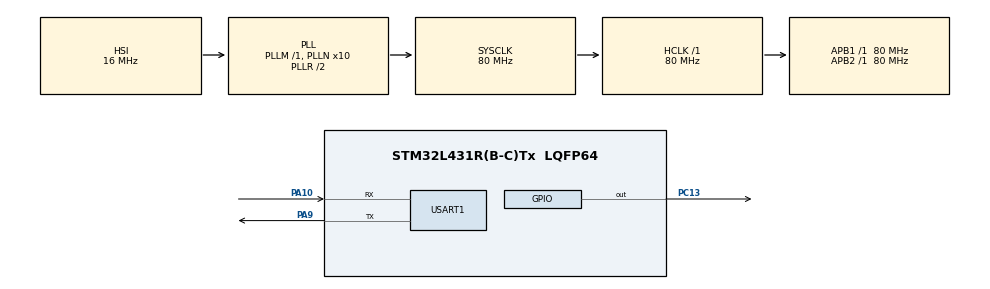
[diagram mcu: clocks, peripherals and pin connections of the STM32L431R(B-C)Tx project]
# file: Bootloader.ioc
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Mcu.Family=STM32L4
Mcu.Name=STM32L431R(B-C)Tx
Mcu.Package=LQFP64
NVIC.PriorityGroup=NVIC_PRIORITYGROUP_4
NVIC.USART1_IRQn=true\:1\:0\:true\:false\:true\:true\:true\:true
PA10.Mode=Asynchronous
PA10.Signal=USART1_RX
PA13\ (JTMS-SWDIO).Mode=Serial_Wire
PA13\ (JTMS-SWDIO).Signal=SYS_JTMS-SWDIO
PA14\ (JTCK-SWCLK).Mode=Serial_Wire
PA14\ (JTCK-SWCLK).Signal=SYS_JTCK-SWCLK
PA9.Mode=Asynchronous
PA9.Signal=USART1_TX
PC13.Signal=GPIO_Output
ProjectManager.HeapSize=0x200
ProjectManager.StackSize=0x400
ProjectManager.TargetToolchain=STM32CubeIDE
RCC.ADCFreq_Value=64000000
RCC.AHBFreq_Value=80000000
RCC.APB1Freq_Value=80000000
RCC.APB1TimFreq_Value=80000000
RCC.APB2Freq_Value=80000000
RCC.APB2TimFreq_Value=80000000
RCC.CortexFreq_Value=80000000
RCC.HCLKFreq_Value=80000000
RCC.HSE_VALUE=16000000
RCC.HSI48_VALUE=48000000
RCC.HSI_VALUE=16000000
RCC.LSE_VALUE=32768
RCC.MSI_VALUE=4000000
RCC.PLLN=10
RCC.PLLSourceVirtual=RCC_PLLSOURCE_HSI
RCC.SYSCLKFreq_VALUE=80000000
RCC.SYSCLKSource=RCC_SYSCLKSOURCE_PLLCLK
RCC.VCOOutputFreq_Value=160000000
USART1.VirtualMode-Asynchronous=VM_ASYNC
VP_IWDG_VS_IWDG.Mode=IWDG_Activate
board=custom

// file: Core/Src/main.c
/* USER CODE BEGIN Header */
/**
 ******************************************************************************
 * @file           : main.c
 * @brief          : Main program body
 ******************************************************************************
 * @attention
 *
 * Copyright (c) 2024 STMicroelectronics.
 * All rights reserved.
 *
 * This software is licensed under terms that can be found in the LICENSE file
 * in the root directory of this software component.
 * If no LICENSE file comes with this software, it is provided AS-IS.
 *
 ******************************************************************************
 */
/* USER CODE END Header */
#include "main.h"

/* USER CODE BEGIN Includes */
#include <string.h>
#include <stdlib.h>
#include "foo.h"
#include "wdt.h"
#include "flash.h"
#include "task_list.h"
#include "bootloader.h"
/* USER CODE END Includes */

/* USER CODE BEGIN PD */
#define HW_VERSION 	0x7d2
#define FW_VERSION 	0x12
#define PROT_VER	0x1000
#define WAIT_TOFF	(0x3E8 * 600)
/* USER CODE END PD */

IWDG_HandleTypeDef hiwdg;

UART_HandleTypeDef huart1;

/* USER CODE BEGIN PV */
static struct foo_device dev;
static struct task_queue  serial_queue;
/* USER CODE END PV */

void SystemClock_Config(void);
static void MX_GPIO_Init(void);
static void MX_USART1_UART_Init(void);
static void MX_IWDG_Init(void);
/* USER CODE BEGIN PFP */
static boot_options_t get_flag(void);
/* USER CODE END PFP */

/* USER CODE BEGIN 0 */

void uart_receive(struct serdev_device *dev, u8 *buf, u32 len) {
	struct task_struct *task = (struct task_struct *)buf;
	put_task_to_queue(&serial_queue, *task);
	serial_start_receiving(dev);
}

/* USER CODE END 0 */

int main(void)
{
  /* USER CODE BEGIN 1 */
	init_queue(&serial_queue, 5);
	dev.serial.bus = &huart1;
	dev.serial.receive_buf = uart_receive;
	dev.button_trigger = 1;
	dev.firmware_version = FW_VERSION;
	dev.hardware_version = HW_VERSION;
	dev.protocol_version = PROT_VER;
	dev.watting_time_off = WAIT_TOFF;
	get_serial_number(&dev);

#ifdef FLASH_LARGE
  dev.firmware_address = FIRMWARE_TEM;
#else
	dev.firmware_address = FIRMWARE_ADDRESS;
#endif
  /* USER CODE END 1 */

  /* MCU Configuration--------------------------------------------------------*/

  /* Reset of all peripherals, Initializes the Flash interface and the Systick. */
  HAL_Init();

  /* Configure the system clock */
  SystemClock_Config();

  /* Initialize all configured peripherals */
  MX_GPIO_Init();
  MX_USART1_UART_Init();
  MX_IWDG_Init();
  /* USER CODE BEGIN 2 */
  serdev_device_register(&dev.serial);
	watchdog_set_timeout(&hiwdg, TIMEOUT_32_SEC);
	HAL_GPIO_WritePin(GPIOC, GPIO_PIN_13, GPIO_PIN_RESET);

	boot_options_t flag_r = get_flag();
	switch (flag_r) {
		case UPDATE_MODE:
			u32 size = 0;
			flash_read(VAR_BASE_ADDRESS + FW_LENGTH_OFFSET, &size, sizeof(u32));
			update_firmware(size);
			boot_options_t flag = BOOTING_MODE;
			flash_write_data(VAR_BASE_ADDRESS + FLAG_OFFSET, (u8 *)&flag, sizeof(boot_options_t));
			HAL_NVIC_SystemReset();
			break;

		case BOOTLOADER_MODE:
			serial_start_receiving(&dev.serial);
			break;

		default:
			goto_application();
	}

  /* USER CODE END 2 */

  /* Infinite loop */
	while (1) {

    /* USER CODE BEGIN 3 */
		if (!queue_is_empty(&serial_queue)) {
			handle_request(&dev, get_new_task(&serial_queue).buf);
		}
		ping_to_watchdog(&hiwdg);
	}
  /* USER CODE END 3 */
}

void SystemClock_Config(void)
{
  RCC_OscInitTypeDef RCC_OscInitStruct = {0};
  RCC_ClkInitTypeDef RCC_ClkInitStruct = {0};

  /** Configure the main internal regulator output voltage
  */
  if (HAL_PWREx_ControlVoltageScaling(PWR_REGULATOR_VOLTAGE_SCALE1) != HAL_OK)
  {
    Error_Handler();
  }

  /** Initializes the RCC Oscillators according to the specified parameters
  * in the RCC_OscInitTypeDef structure.
  */
  RCC_OscInitStruct.OscillatorType = RCC_OSCILLATORTYPE_HSI|RCC_OSCILLATORTYPE_LSI;
  RCC_OscInitStruct.HSIState = RCC_HSI_ON;
  RCC_OscInitStruct.HSICalibrationValue = RCC_HSICALIBRATION_DEFAULT;
  RCC_OscInitStruct.LSIState = RCC_LSI_ON;
  RCC_OscInitStruct.PLL.PLLState = RCC_PLL_ON;
  RCC_OscInitStruct.PLL.PLLSource = RCC_PLLSOURCE_HSI;
  RCC_OscInitStruct.PLL.PLLM = 1;
  RCC_OscInitStruct.PLL.PLLN = 10;
  RCC_OscInitStruct.PLL.PLLP = RCC_PLLP_DIV7;
  RCC_OscInitStruct.PLL.PLLQ = RCC_PLLQ_DIV2;
  RCC_OscInitStruct.PLL.PLLR = RCC_PLLR_DIV2;
  if (HAL_RCC_OscConfig(&RCC_OscInitStruct) != HAL_OK)
  {
    Error_Handler();
  }

  /** Initializes the CPU, AHB and APB buses clocks
  */
  RCC_ClkInitStruct.ClockType = RCC_CLOCKTYPE_HCLK|RCC_CLOCKTYPE_SYSCLK
                              |RCC_CLOCKTYPE_PCLK1|RCC_CLOCKTYPE_PCLK2;
  RCC_ClkInitStruct.SYSCLKSource = RCC_SYSCLKSOURCE_PLLCLK;
  RCC_ClkInitStruct.AHBCLKDivider = RCC_SYSCLK_DIV1;
  RCC_ClkInitStruct.APB1CLKDivider = RCC_HCLK_DIV1;
  RCC_ClkInitStruct.APB2CLKDivider = RCC_HCLK_DIV1;

  if (HAL_RCC_ClockConfig(&RCC_ClkInitStruct, FLASH_LATENCY_4) != HAL_OK)
  {
    Error_Handler();
  }
}

static void MX_IWDG_Init(void)
{

  hiwdg.Instance = IWDG;
  hiwdg.Init.Prescaler = IWDG_PRESCALER_4;
  hiwdg.Init.Window = 4095;
  hiwdg.Init.Reload = 4095;
  if (HAL_IWDG_Init(&hiwdg) != HAL_OK)
  {
    Error_Handler();
  }

}

static void MX_USART1_UART_Init(void)
{

  huart1.Instance = USART1;
  huart1.Init.BaudRate = 115200;
  huart1.Init.WordLength = UART_WORDLENGTH_8B;
  huart1.Init.StopBits = UART_STOPBITS_1;
  huart1.Init.Parity = UART_PARITY_NONE;
  huart1.Init.Mode = UART_MODE_TX_RX;
  huart1.Init.HwFlowCtl = UART_HWCONTROL_NONE;
  huart1.Init.OverSampling = UART_OVERSAMPLING_16;
  huart1.Init.OneBitSampling = UART_ONE_BIT_SAMPLE_DISABLE;
  huart1.AdvancedInit.AdvFeatureInit = UART_ADVFEATURE_NO_INIT;
  if (HAL_UART_Init(&huart1) != HAL_OK)
  {
    Error_Handler();
  }

}

static void MX_GPIO_Init(void)
{
  GPIO_InitTypeDef GPIO_InitStruct = {0};

  /* GPIO Ports Clock Enable */
  __HAL_RCC_GPIOC_CLK_ENABLE();
  __HAL_RCC_GPIOA_CLK_ENABLE();

  /*Configure GPIO pin Output Level */
  HAL_GPIO_WritePin(GPIOC, GPIO_PIN_13, GPIO_PIN_RESET);

  /*Configure GPIO pin : PC13 */
  GPIO_InitStruct.Pin = GPIO_PIN_13;
  GPIO_InitStruct.Mode = GPIO_MODE_OUTPUT_PP;
  GPIO_InitStruct.Pull = GPIO_NOPULL;
  GPIO_InitStruct.Speed = GPIO_SPEED_FREQ_LOW;
  HAL_GPIO_Init(GPIOC, &GPIO_InitStruct);

}

/* USER CODE BEGIN 4 */
static boot_options_t get_flag(void) {
	boot_options_t flag = BOOTING_MODE;
	flash_read(VAR_BASE_ADDRESS + FLAG_OFFSET, &flag, sizeof(boot_options_t));
	return flag;
}

/* USER CODE END 4 */

void Error_Handler(void)
{
	__disable_irq();
	while (1) {
	}
}
